# MCXA156 register map
Vendor: nxp.com; File version: 1.0
CPU: CM33 r2p0, little endian, no MPU, FPU, VTOR, 3 interrupt priority bits
Registers are 32-bit, read-write, reset 0x0 unless marked. A register's access mark holds for its fields unless they carry their own. Offsets are from the block's base; [hi:lo] are bit positions; {n}, {i} and the like mark numbered series; 'fields as' and 'values as' point back to an identical list.

## PORT1 — PORT
Base 0x400BD000
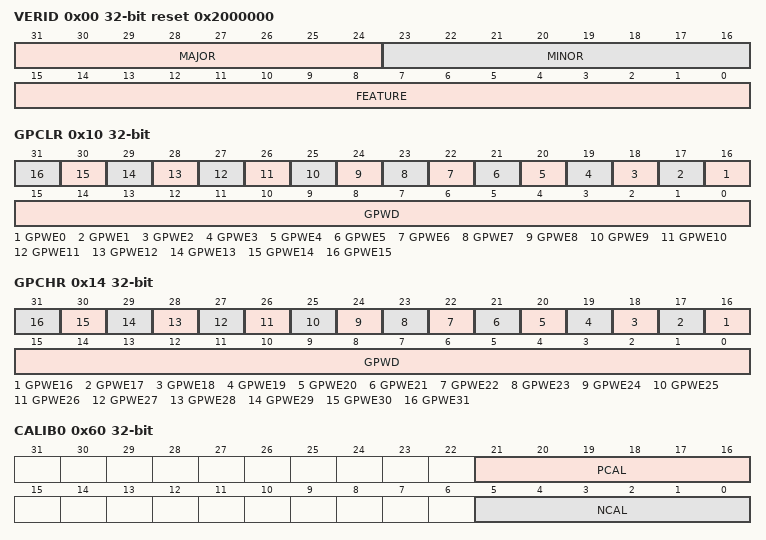
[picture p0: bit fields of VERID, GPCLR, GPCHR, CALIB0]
0x00 VERID ro reset 0x2000000 — Version ID
  [31:24] MAJOR — Major Version Number
  [23:16] MINOR — Minor Version Number
  [15:0] FEATURE — Feature Specification Number
    0=Basic implementation
0x10 GPCLR — Global Pin Control Low
  [n+16] GPWE{n} (n=0..15) — Global Pin Write Enable
    0=gpwe0 (Not updated); 1=gpwe1 (Updated)
  [15:0] GPWD — Global Pin Write Data
0x14 GPCHR — Global Pin Control High
  [n] GPWE{n} (n=16..31) — Global Pin Write Enable
    0=gpwe0 (Not updated); 1=gpwe1 (Updated)
  [15:0] GPWD — Global Pin Write Data
0x20 CONFIG — Configuration
  [0] RANGE — Port Voltage Range
    0=1.71 V-3.6 V; 1=2.70 V-3.6 V
0x60 CALIB0 (reset mask 0xFFC0FFC0) — Calibration 0
  [21:16] PCAL — Calibration of PMOS Output Driver
  [5:0] NCAL — Calibration of NMOS Output Driver
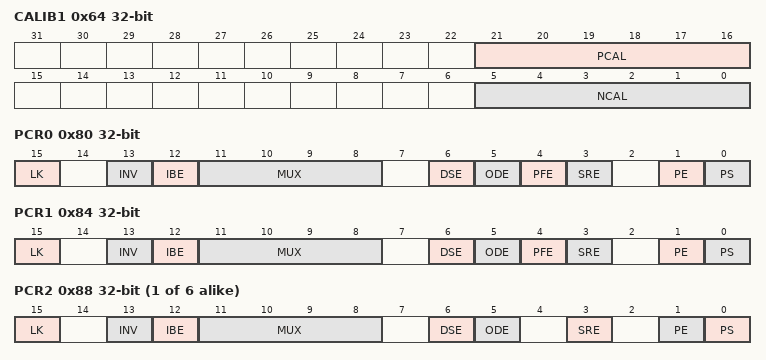
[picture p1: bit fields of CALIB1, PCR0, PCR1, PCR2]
0x64 CALIB1 (reset mask 0xFFC0FFC0) — Calibration 1
  fields as CALIB0
0x80 PCR0 — Pin Control 0
  [15] LK — Lock Register
    0=Does not lock; 1=Locks
  [13] INV — Invert Input
    0=Does not invert; 1=Inverts
  [12] IBE — Input Buffer Enable
    0=Disables; 1=Enables
  [11:8] MUX — Pin Multiplex Control
    0=Alternative 0 (GPIO); {v}=Alternative {v} (chip-specific) (v=1..13)
  [6] DSE — Drive Strength Enable
    0=Low; 1=High
  [5] ODE — Open Drain Enable
    0=Disables; 1=Enables
  [4] PFE — Passive Filter Enable
    0=Disables; 1=Enables
  [3] SRE — Slew Rate Enable
    0=Fast; 1=Slow
  [1] PE — Pull Enable
    0=Disables; 1=Enables
  [0] PS — Pull Select
    0=Enables internal pulldown resistor; 1=Enables internal pullup resistor
0x84 PCR1 — Pin Control 1
  fields as PCR0
{0x80+4i} PCR{i} (i=2..7) — Pin Control {i}
  [15] LK — Lock Register
    0=Does not lock; 1=Locks
  [13] INV — Invert Input
    0=Does not invert; 1=Inverts
  [12] IBE — Input Buffer Enable
    0=Disables; 1=Enables
  [11:8] MUX — Pin Multiplex Control
    values as PCR0.MUX
  [6] DSE — Drive Strength Enable
    0=Low; 1=High
  [5] ODE — Open Drain Enable
    0=Disables; 1=Enables
  [3] SRE — Slew Rate Enable
    0=Fast; 1=Slow
  [1] PE — Pull Enable
    0=Disables; 1=Enables
  [0] PS — Pull Select
    values as PCR0.PS
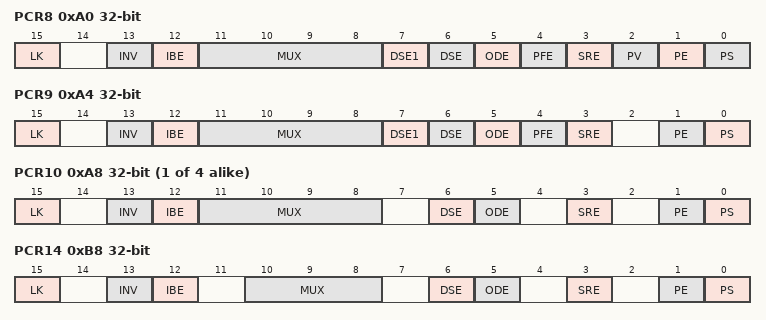
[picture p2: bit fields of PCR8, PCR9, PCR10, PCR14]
0xA0 PCR8 — Pin Control 8
  [15] LK — Lock Register
    0=Does not lock; 1=Locks
  [13] INV — Invert Input
    0=Does not invert; 1=Inverts
  [12] IBE — Input Buffer Enable
    0=Disables; 1=Enables
  [11:8] MUX — Pin Multiplex Control
    values as PCR0.MUX
  [7] DSE1 — Drive Strength Enable
    0=Normal; 1=Double
  [6] DSE — Drive Strength Enable
    0=Low; 1=High
  [5] ODE — Open Drain Enable
    0=Disables; 1=Enables
  [4] PFE — Passive Filter Enable
    0=Disables; 1=Enables
  [3] SRE — Slew Rate Enable
    0=Fast; 1=Slow
  [2] PV — Pull Value
    0=Low; 1=High
  [1] PE — Pull Enable
    0=Disables; 1=Enables
  [0] PS — Pull Select
    values as PCR0.PS
0xA4 PCR9 — Pin Control 9
  [15] LK — Lock Register
    0=Does not lock; 1=Locks
  [13] INV — Invert Input
    0=Does not invert; 1=Inverts
  [12] IBE — Input Buffer Enable
    0=Disables; 1=Enables
  [11:8] MUX — Pin Multiplex Control
    values as PCR0.MUX
  [7] DSE1 — Drive Strength Enable
    0=Normal; 1=Double
  [6] DSE — Drive Strength Enable
    0=Low; 1=High
  [5] ODE — Open Drain Enable
    0=Disables; 1=Enables
  [4] PFE — Passive Filter Enable
    0=Disables; 1=Enables
  [3] SRE — Slew Rate Enable
    0=Fast; 1=Slow
  [1] PE — Pull Enable
    0=Disables; 1=Enables
  [0] PS — Pull Select
    values as PCR0.PS
{0x80+4i} PCR{i} (i=10..13) — Pin Control {i}
  fields as PCR2
0xB8 PCR14 — Pin Control 14
  [15] LK — Lock Register
    0=Does not lock; 1=Locks
  [13] INV — Invert Input
    0=Does not invert; 1=Inverts
  [12] IBE — Input Buffer Enable
    0=Disables; 1=Enables
  [10:8] MUX — Pin Multiplex Control
    0=Alternative 0 (GPIO); {v}=Alternative {v} (chip-specific) (v=1..7)
  [6] DSE — Drive Strength Enable
    0=Low; 1=High
  [5] ODE — Open Drain Enable
    0=Disables; 1=Enables
  [3] SRE — Slew Rate Enable
    0=Fast; 1=Slow
  [1] PE — Pull Enable
    0=Disables; 1=Enables
  [0] PS — Pull Select
    values as PCR0.PS
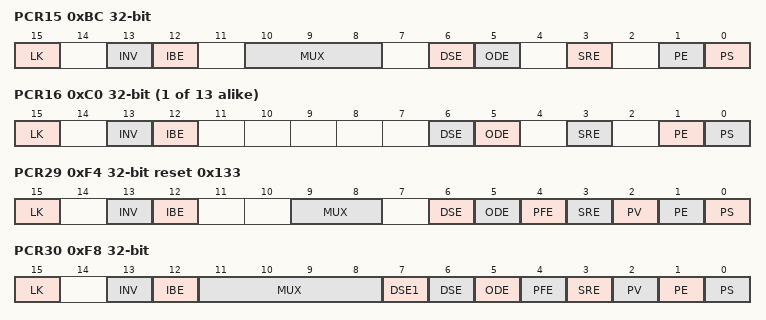
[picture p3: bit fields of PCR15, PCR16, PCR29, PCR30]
0xBC PCR15 — Pin Control 15
  fields as PCR14
{0x80+4i} PCR{i} (i=16..28) — Pin Control {i}
  [15] LK — Lock Register
    0=Does not lock; 1=Locks
  [13] INV — Invert Input
    0=Does not invert; 1=Inverts
  [12] IBE — Input Buffer Enable
    0=Disables; 1=Enables
  [6] DSE — Drive Strength Enable
    0=Low; 1=High
  [5] ODE — Open Drain Enable
    0=Disables; 1=Enables
  [3] SRE — Slew Rate Enable
    0=Fast; 1=Slow
  [1] PE — Pull Enable
    0=Disables; 1=Enables
  [0] PS — Pull Select
    values as PCR0.PS
0xF4 PCR29 reset 0x133 — Pin Control 29
  [15] LK — Lock Register
    0=Does not lock; 1=Locks
  [13] INV — Invert Input
    0=Does not invert; 1=Inverts
  [12] IBE — Input Buffer Enable
    0=Disables; 1=Enables
  [9:8] MUX — Pin Multiplex Control
    0=Alternative 0 (GPIO); 1=Alternative 1 (chip-specific); 2=Alternative 2 (chip-specific); 3=Alternative 3 (chip-specific)
  [6] DSE — Drive Strength Enable
    0=Low; 1=High
  [5] ODE — Open Drain Enable
    0=Disables; 1=Enables
  [4] PFE — Passive Filter Enable
    0=Disables; 1=Enables
  [3] SRE — Slew Rate Enable
    0=Fast; 1=Slow
  [2] PV — Pull Value
    0=Low; 1=High
  [1] PE — Pull Enable
    0=Disables; 1=Enables
  [0] PS — Pull Select
    values as PCR0.PS
0xF8 PCR30 — Pin Control 30
  fields as PCR8
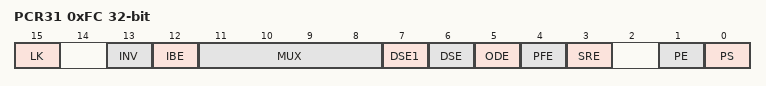
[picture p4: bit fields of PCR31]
0xFC PCR31 — Pin Control 31
  fields as PCR9
